# PY32F071Cxx register map
Vendor: Puya; Series: PY32F0; File version: 1.0.0
CPU: CM0+ r0p1, little endian, no MPU, no FPU, 4 interrupt priority bits
Registers are 32-bit, read-write, reset 0x0 unless marked. A register's access mark holds for its fields unless they carry their own. Offsets are from the block's base; [hi:lo] are bit positions; {n}, {i} and the like mark numbered series; 'fields as' and 'values as' point back to an identical list.

## FLASH
Base 0x40022000
0x00 ACR reset 0x500
  [1:0] LATENCY
    1=0; 2=1
0x08 KEYR wo
  [31:0] KEY
0x0C OPTKEYR wo
  [31:0] OPTKEY
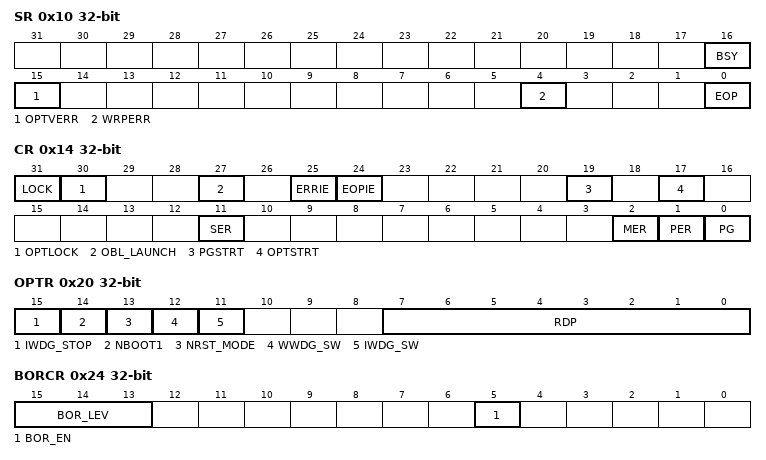
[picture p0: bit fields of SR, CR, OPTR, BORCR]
0x10 SR
  [16] BSY ro, [15] OPTVERR, [4] WRPERR, [0] EOP
0x14 CR
  [31] LOCK, [30] OPTLOCK, [27] OBL_LAUNCH, [25] ERRIE, [24] EOPIE, [19] PGSTRT, [17] OPTSTRT, [11] SER, [2] MER, [1] PER, [0] PG
0x20 OPTR ro
  [15] IWDG_STOP
  [14] NBOOT1
  [13] NRST_MODE
  [12] WWDG_SW
  [11] IWDG_SW
  [7:0] RDP
    85=LEVEL_1; 170=LEVEL_0
0x24 BORCR ro
  [15:13] BOR_LEV, [5] BOR_EN
0x2C WRPR
  [15:0] WRP
    1=0; 2=1; 4=2; 8=3; 16=4; 32=5; 64=6; 128=7; 0x100=8; 0x200=9; 0x400=10; 0x800=11; 0x1000=12; 0x2000=13; 0x4000=14; 0x8000=15
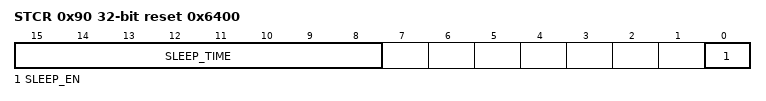
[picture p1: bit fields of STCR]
0x90 STCR reset 0x6400
  [15:8] SLEEP_TIME, [0] SLEEP_EN
0x100 TS0 reset 0xB4
  [7:0] TS0
    1=0; 2=1; 4=2; 8=3; 16=4; 32=5; 64=6; 128=7
0x104 TS1 reset 0x1B0
  [8:0] TS1
    1=0; 2=1; 4=2; 8=3; 16=4; 32=5; 64=6; 128=7; 0x100=8
0x108 TS2P reset 0xB4
  [7:0] TS2P
    1=0; 2=1; 4=2; 8=3; 16=4; 32=5; 64=6; 128=7
0x10C TPS3 reset 0x6C0
  [10:0] TPS3
    1=0; 2=1; 4=2; 8=3; 16=4; 32=5; 64=6; 128=7; 0x100=8; 0x200=9; 0x400=10
0x110 TS3 reset 0xB4
  [7:0] TS3
    1=0; 2=1; 4=2; 8=3; 16=4; 32=5; 64=6; 128=7
0x114 PERTPE reset 0xEA60
  [16:0] PERTPE
    1=0; 2=1; 4=2; 8=3; 16=4; 32=5; 64=6; 128=7; 0x100=8; 0x200=9; 0x400=10; 0x800=11; 0x1000=12; 0x2000=13; 0x4000=14; 0x8000=15; 0x10000=16
0x118 SMERTPE reset 0xFD20
  [16:0] SMERTPE
    values as PERTPE.PERTPE
0x11C PRGTPE reset 0x8CA0
  [15:0] PRGTPE
    values as WRPR.WRP
0x120 PRETPE reset 0x12C0
  [13:0] PRETPE
    1=0; 2=1; 4=2; 8=3; 16=4; 32=5; 64=6; 128=7; 0x100=8; 0x200=9; 0x400=10; 0x800=11; 0x1000=12; 0x2000=13

## GPIOA — General-purpose I/Os
Base 0x50000000
Same registers: GPIOB 0x50000400, GPIOC 0x50000800, GPIOF 0x50001400
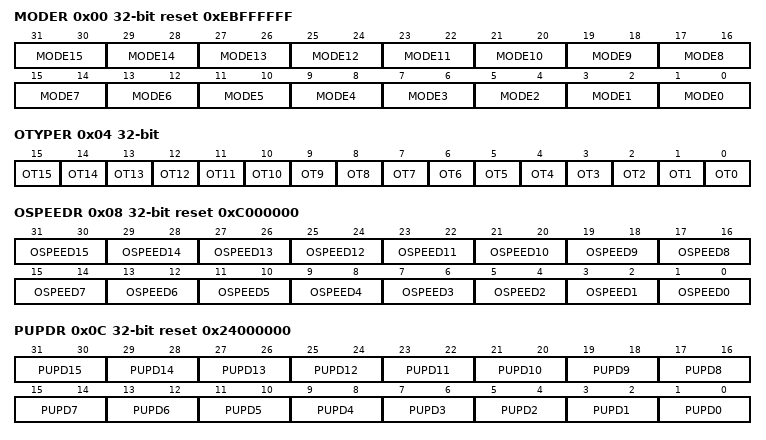
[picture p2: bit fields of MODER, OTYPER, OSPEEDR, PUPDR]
0x00 MODER reset 0xEBFFFFFF — GPIO port mode register
  [all] fields
    1=0; 2=1
  [2n+1:2n] MODE{n} (n=0..15) — Port x configuration bits (y=0-15)
0x04 OTYPER — GPIO port output type register
  [n] OT{n} (n=0..15) — Port x configuration bits (y=0-15)
0x08 OSPEEDR reset 0xC000000 — GPIO port output speed register
  [all] fields
    1=0; 2=1
  [2n+1:2n] OSPEED{n} (n=0..15) — Port x configuration bits (y=0-15)
0x0C PUPDR reset 0x24000000 — GPIO port pull-up/pull-down register
  [all] fields
    1=0; 2=1
  [2n+1:2n] PUPD{n} (n=0..15) — Port x configuration bits (y=0-15)
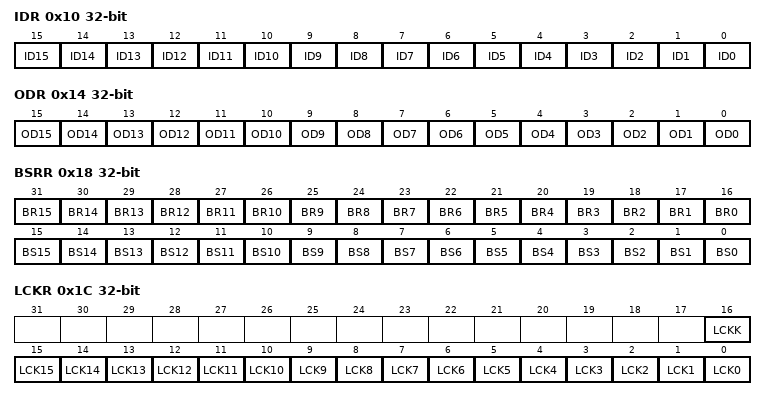
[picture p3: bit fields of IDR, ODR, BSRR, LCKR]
0x10 IDR ro — GPIO port input data register
  [n] ID{n} (n=0..15) — Port input data (y=0-15)
0x14 ODR — GPIO port output data register
  [n] OD{n} (n=0..15) — Port output data (y=0-15)
0x18 BSRR wo — GPIO port bit set/reset register
  [n+16] BR{n} (n=1..15) — Port x reset bit y (y=0-15)
  [16] BR0 — Port x set bit y (y=0-15)
  [n] BS{n} (n=0..15) — Port x set bit y (y=0-15)
0x1C LCKR — GPIO port configuration lock register
  [16] LCKK — Port x lock (LCKK)
  [n] LCK{n} (n=0..15) — Port x lock bit y (y=0-15)
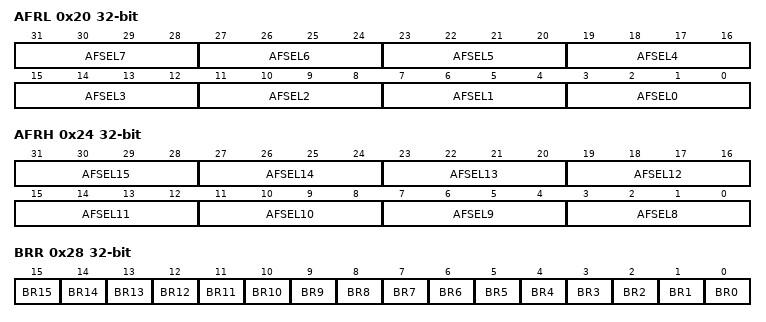
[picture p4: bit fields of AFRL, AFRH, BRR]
0x20 AFRL — GPIO alternate function low register
  [all] fields
    1=0; 2=1; 4=2; 8=3
  [4n+3:4n] AFSEL{n} (n=0..7) — Alternate function selection for port x bit y (y=0-7)
0x24 AFRH — GPIO alternate function high register
  [all] fields
    1=0; 2=1; 4=2; 8=3
  [4n-29:4n-32] AFSEL{n} (n=8..15) — Alternate function selection for port x bit y (y=8-15)
0x28 BRR wo — port bit reset register
  [n] BR{n} (n=0..15) — Port Reset bit

## I2C1 — Inter integrated circuit
Base 0x40005400
Same registers: I2C2 0x40005800
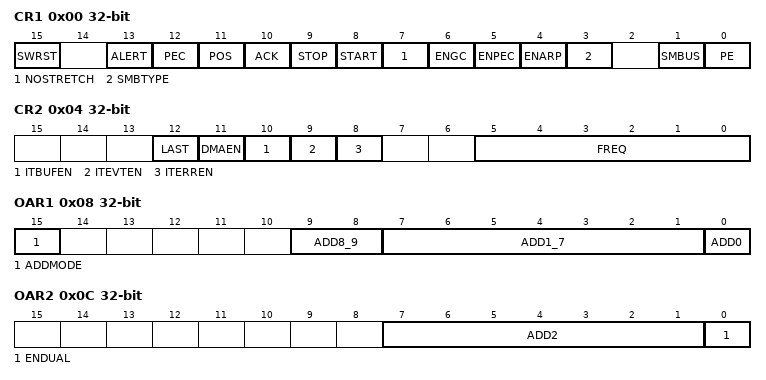
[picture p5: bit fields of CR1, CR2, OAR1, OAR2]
0x00 CR1
  [15] SWRST, [13] ALERT, [12] PEC, [11] POS, [10] ACK, [9] STOP, [8] START, [7] NOSTRETCH, [6] ENGC, [5] ENPEC, [4] ENARP, [3] SMBTYPE, [1] SMBUS, [0] PE
0x04 CR2
  [12] LAST
  [11] DMAEN
  [10] ITBUFEN
  [9] ITEVTEN
  [8] ITERREN
  [5:0] FREQ
    1=0; 2=1; 4=2; 8=3; 16=4; 32=5
0x08 OAR1
  [15] ADDMODE, [9:8] ADD8_9, [7:1] ADD1_7, [0] ADD0
0x0C OAR2
  [7:1] ADD2, [0] ENDUAL
0x10 DR
  [7:0] DR
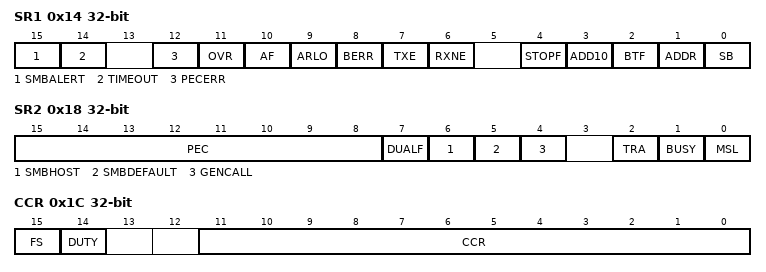
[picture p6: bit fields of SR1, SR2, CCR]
0x14 SR1
  [15] SMBALERT, [14] TIMEOUT, [12] PECERR, [11] OVR, [10] AF, [9] ARLO, [8] BERR, [7] TXE ro, [6] RXNE ro, [4] STOPF ro, [3] ADD10 ro, [2] BTF ro, [1] ADDR ro, [0] SB ro
0x18 SR2 ro
  [15:8] PEC, [7] DUALF, [6] SMBHOST, [5] SMBDEFAULT, [4] GENCALL, [2] TRA, [1] BUSY, [0] MSL
0x1C CCR
  [15] FS, [14] DUTY, [11:0] CCR
0x20 TRISE reset 0x2
  [5:0] TRISE
